AUTOSAR XML (schema 4-2-1)
package /ComponentTypes
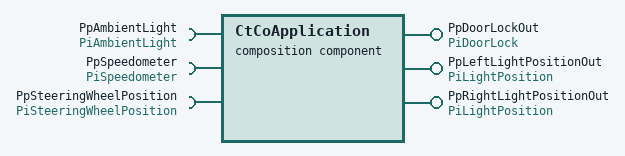
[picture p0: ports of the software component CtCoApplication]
  composition sw component type CtCoApplication
    provide port PpDoorLockOut: nonqueued-sender-com-spec{data-element=DeDoorLock, init-value=0}, provided-interface=PiDoorLock
    provide port PpLeftLightPositionOut: provided-com-specs=[{data-element=DeLightLength, init-value=0}, {data-element=DeLightPosition, init-value=0}], provided-interface=PiLightPosition
    provide port PpRightLightPositionOut: provided-com-specs=[{data-element=DeLightLength, init-value=0}, {data-element=DeLightPosition, init-value=0}], provided-interface=PiLightPosition
    require port PpAmbientLight: nonqueued-receiver-com-spec{data-element=DeAmbientLight, filter=data-filter-type=ALWAYS, init-value=0}, required-interface=PiAmbientLight
    require port PpSpeedometer: nonqueued-receiver-com-spec{data-element=DeSpeedometer, filter=data-filter-type=ALWAYS, init-value=0}, required-interface=PiSpeedometer
    require port PpSteeringWheelPosition: nonqueued-receiver-com-spec{data-element=DeSteeringWheelPosition, filter=data-filter-type=ALWAYS, init-value=constant-reference=CSteeringWheelInitPosition}, required-interface=PiSteeringWheelPosition
    9 x component:
      CpApAFSController: type=CtApAFSController
      CpApBatteryManager: type=CtApBatteryManager
      CpCddIoHwAb: type=CtCddIoHwAb
      CpSaAmbientLight: type=CtSaAmbientLight
      CpSaDoorLock: type=CtSaDoorLock
      CpSaLeftFrontlight: type=CtSaFrontlight
      CpSaRightFrontlight: type=CtSaFrontlight
      CpSaSpeedometer: type=CtSaSpeedometer
      CpSaSteeringWheel: type=CtSaSteeringWheel
    connect CpApAFSController.PpLightPositionLeft -> CpSaLeftFrontlight.PpLightPositionIn
    connect CpApAFSController.PpLightPositionRight -> CpSaRightFrontlight.PpLightPositionIn
    connect CpCddIoHwAb.PpAFSSwitch -> CpApAFSController.PpAFSSwitch
    connect CpCddIoHwAb.PpHighBeam -> CpApAFSController.PpHighBeam
    connect CpCddIoHwAb.PpBatteryManagerCddIoHwAb -> CpApBatteryManager.PpBatteryLevelCddIoHwAb
    connect CpSaAmbientLight.PpAmbientLightOut -> CpApAFSController.PpAmbientLight
    connect CpSaSpeedometer.PpSpeedometerOut -> CpApAFSController.PpSpeedometer
    connect CpSaSteeringWheel.PpSteeringWheelPositionOut -> CpApAFSController.PpSteeringWheelPosition
    delegate CpSaAmbientLight.PpAmbientLightIn <-> outer port PpAmbientLight
    delegate CpSaDoorLock.PpDoorLockOut <-> outer port PpDoorLockOut
    delegate CpSaLeftFrontlight.PpLightPositionOut <-> outer port PpLeftLightPositionOut
    delegate CpSaRightFrontlight.PpLightPositionOut <-> outer port PpRightLightPositionOut
    delegate CpSaDoorLock.PpSpeedometerIn <-> outer port PpSpeedometer
    delegate CpSaSpeedometer.PpSpeedometerIn <-> outer port PpSpeedometer
    delegate CpSaSteeringWheel.PpSteeringWheelPositionIn <-> outer port PpSteeringWheelPosition
